# RZG2L register map
Vendor: Renesas; Series: All Chips; File version: x.xx
Renesas RZ/G2L All MPU
Registers are 32-bit, access not given, no defined reset value unless marked. A register's access mark holds for its fields unless they carry their own. Offsets are from the block's base; lines under a group give offsets from that group; [hi:lo] are bit positions; {n}, {i} and the like mark numbered series; 'fields as' and 'values as' point back to an identical list; <NAME> marks a mode.

## Memory map
{0x40048000+0x100*n} GPT32E{n} (n=0..7)
0x40048800 POEGA
0x40048C00 POEGB
0x40049000 POEGC
0x40049400 POEGD
0x4004AC00 RSPI0
0x4004B000 RSPI1
0x4004B400 RSPI2
0x4004B800 SCIFA0
0x4004BC00 SCIFA1
0x4004C000 SCIFA2
0x4004C400 SCIFA3
0x4004C800 SCIFA4
0x40058000 RIIC0
0x40058400 RIIC1
0x40058800 RIIC2
0x40058C00 RIIC3
0x40060000 SPIBSC
0x40400000 MHU0
0x40400020 MHU1
0x40400040 MHU2
0x40400060 MHU3
0x40400080 MHU4
0x404000A0 MHU5
0x40400800 MHU_SWINT0
0x40400810 MHU_SWINT1
0x40400820 MHU_SWINT2
0x40400830 MHU_SWINT3
0x41010000 CPG
0x41020200 SYSC
0x41030010 GPIO
0x410B0000 INTC_IM33
0x42800400 WDT2
0x42800800 WDT0
0x42800C00 WDT1
0x42801000 GTM0
0x42801400 GTM1
0x42801800 GTM2

## GPT32E0
Base 0x40048000
Same registers: GPT32E1 0x40048100, GPT32E2 0x40048200, GPT32E3 0x40048300, GPT32E4 0x40048400, GPT32E5 0x40048500, GPT32E6 0x40048600, GPT32E7 0x40048700
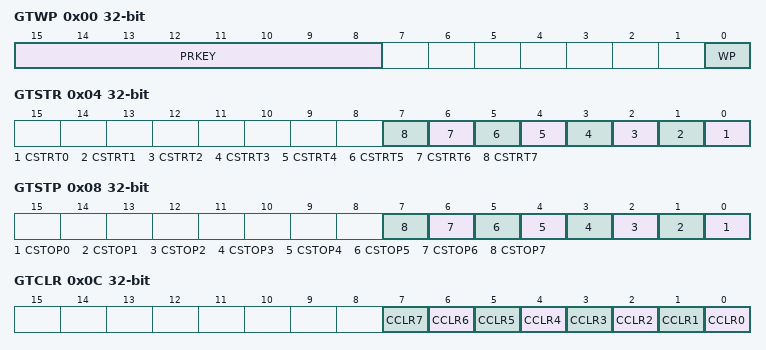
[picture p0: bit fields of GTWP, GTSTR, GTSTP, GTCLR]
0x00 GTWP
  [15:8] PRKEY, [0] WP
0x04 GTSTR
  [n] CSTRT{n} (n=0..7)
0x08 GTSTP
  [n] CSTOP{n} (n=0..7)
0x0C GTCLR
  [n] CCLR{n} (n=0..7)
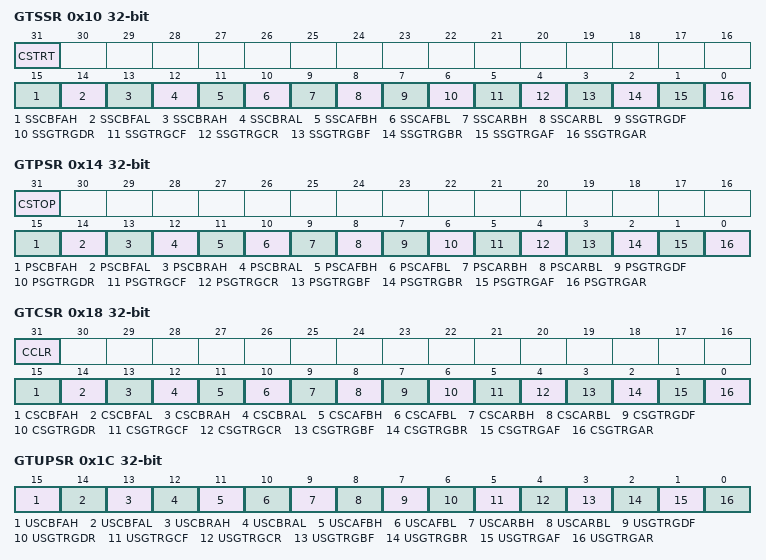
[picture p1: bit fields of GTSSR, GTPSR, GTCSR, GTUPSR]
0x10 GTSSR
  [31] CSTRT, [15] SSCBFAH, [14] SSCBFAL, [13] SSCBRAH, [12] SSCBRAL, [11] SSCAFBH, [10] SSCAFBL, [9] SSCARBH, [8] SSCARBL, [7] SSGTRGDF, [6] SSGTRGDR, [5] SSGTRGCF, [4] SSGTRGCR, [3] SSGTRGBF, [2] SSGTRGBR, [1] SSGTRGAF, [0] SSGTRGAR
0x14 GTPSR
  [31] CSTOP, [15] PSCBFAH, [14] PSCBFAL, [13] PSCBRAH, [12] PSCBRAL, [11] PSCAFBH, [10] PSCAFBL, [9] PSCARBH, [8] PSCARBL, [7] PSGTRGDF, [6] PSGTRGDR, [5] PSGTRGCF, [4] PSGTRGCR, [3] PSGTRGBF, [2] PSGTRGBR, [1] PSGTRGAF, [0] PSGTRGAR
0x18 GTCSR
  [31] CCLR, [15] CSCBFAH, [14] CSCBFAL, [13] CSCBRAH, [12] CSCBRAL, [11] CSCAFBH, [10] CSCAFBL, [9] CSCARBH, [8] CSCARBL, [7] CSGTRGDF, [6] CSGTRGDR, [5] CSGTRGCF, [4] CSGTRGCR, [3] CSGTRGBF, [2] CSGTRGBR, [1] CSGTRGAF, [0] CSGTRGAR
0x1C GTUPSR
  [15] USCBFAH, [14] USCBFAL, [13] USCBRAH, [12] USCBRAL, [11] USCAFBH, [10] USCAFBL, [9] USCARBH, [8] USCARBL, [7] USGTRGDF, [6] USGTRGDR, [5] USGTRGCF, [4] USGTRGCR, [3] USGTRGBF, [2] USGTRGBR, [1] USGTRGAF, [0] USGTRGAR
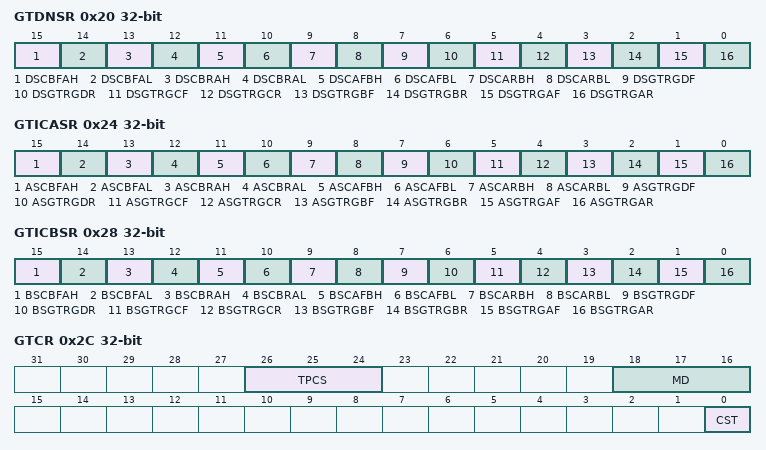
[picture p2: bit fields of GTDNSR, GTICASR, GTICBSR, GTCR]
0x20 GTDNSR
  [15] DSCBFAH, [14] DSCBFAL, [13] DSCBRAH, [12] DSCBRAL, [11] DSCAFBH, [10] DSCAFBL, [9] DSCARBH, [8] DSCARBL, [7] DSGTRGDF, [6] DSGTRGDR, [5] DSGTRGCF, [4] DSGTRGCR, [3] DSGTRGBF, [2] DSGTRGBR, [1] DSGTRGAF, [0] DSGTRGAR
0x24 GTICASR
  [15] ASCBFAH, [14] ASCBFAL, [13] ASCBRAH, [12] ASCBRAL, [11] ASCAFBH, [10] ASCAFBL, [9] ASCARBH, [8] ASCARBL, [7] ASGTRGDF, [6] ASGTRGDR, [5] ASGTRGCF, [4] ASGTRGCR, [3] ASGTRGBF, [2] ASGTRGBR, [1] ASGTRGAF, [0] ASGTRGAR
0x28 GTICBSR
  [15] BSCBFAH, [14] BSCBFAL, [13] BSCBRAH, [12] BSCBRAL, [11] BSCAFBH, [10] BSCAFBL, [9] BSCARBH, [8] BSCARBL, [7] BSGTRGDF, [6] BSGTRGDR, [5] BSGTRGCF, [4] BSGTRGCR, [3] BSGTRGBF, [2] BSGTRGBR, [1] BSGTRGAF, [0] BSGTRGAR
0x2C GTCR
  [26:24] TPCS, [18:16] MD, [0] CST
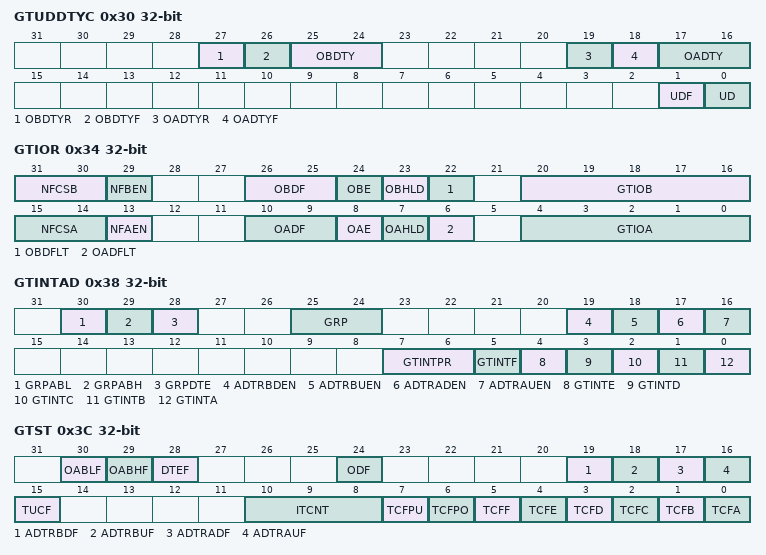
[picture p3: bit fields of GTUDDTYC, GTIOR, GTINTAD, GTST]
0x30 GTUDDTYC
  [27] OBDTYR, [26] OBDTYF, [25:24] OBDTY, [19] OADTYR, [18] OADTYF, [17:16] OADTY, [1] UDF, [0] UD
0x34 GTIOR
  [31:30] NFCSB, [29] NFBEN, [26:25] OBDF, [24] OBE, [23] OBHLD, [22] OBDFLT, [20:16] GTIOB, [15:14] NFCSA, [13] NFAEN, [10:9] OADF, [8] OAE, [7] OAHLD, [6] OADFLT, [4:0] GTIOA
0x38 GTINTAD
  [30] GRPABL, [29] GRPABH, [28] GRPDTE, [25:24] GRP, [19] ADTRBDEN, [18] ADTRBUEN, [17] ADTRADEN, [16] ADTRAUEN, [7:6] GTINTPR, [5] GTINTF, [4] GTINTE, [3] GTINTD, [2] GTINTC, [1] GTINTB, [0] GTINTA
0x3C GTST
  [30] OABLF, [29] OABHF, [28] DTEF, [24] ODF, [19] ADTRBDF, [18] ADTRBUF, [17] ADTRADF, [16] ADTRAUF, [15] TUCF, [10:8] ITCNT, [7] TCFPU, [6] TCFPO, [5] TCFF, [4] TCFE, [3] TCFD, [2] TCFC, [1] TCFB, [0] TCFA
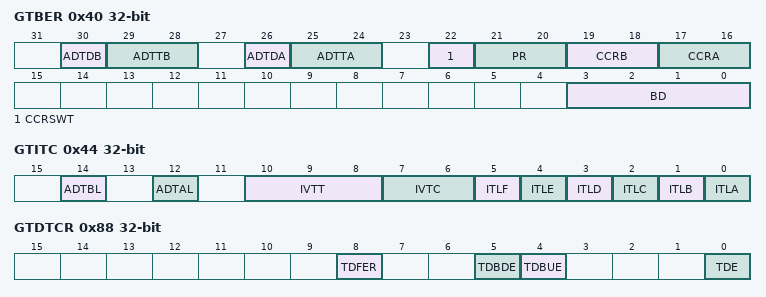
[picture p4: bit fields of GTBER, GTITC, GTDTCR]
0x40 GTBER
  [30] ADTDB, [29:28] ADTTB, [26] ADTDA, [25:24] ADTTA, [22] CCRSWT, [21:20] PR, [19:18] CCRB, [17:16] CCRA, [3:0] BD
0x44 GTITC
  [14] ADTBL, [12] ADTAL, [10:8] IVTT, [7:6] IVTC, [5] ITLF, [4] ITLE, [3] ITLD, [2] ITLC, [1] ITLB, [0] ITLA
0x48 GTCNT
0x4C GTCCRA
0x50 GTCCRB
0x54 GTCCRC
0x58 GTCCRE
0x5C GTCCRD
0x60 GTCCRF
0x64 GTPR
0x68 GTPBR
0x6C GTPDBR
0x70 GTADTRA
0x74 GTADTBRA
0x78 GTADTDBRA
0x7C GTADTRB
0x80 GTADTBRB
0x84 GTADTDBRB
0x88 GTDTCR
  [8] TDFER, [5] TDBDE, [4] TDBUE, [0] TDE
0x8C GTDVU
0x90 GTDVD
0x94 GTDBU
0x98 GTDBD
0x9C GTSOS
  [1:0] SOS
0xA0 GTSOTR
  [0] SOTR
